# ATxmega128A1U device description
Architecture: AVR8_XMEGA; Family: AVR XMEGA
Registers are 8-bit, access not given, no defined reset value unless marked. A register's access mark holds for its fields unless they carry their own. Offsets are from the block's base; [hi:lo] are bit positions; {n}, {i} and the like mark numbered series; 'fields as' and 'values as' point back to an identical list.

## MCU — MCU Control
Instances: MCU 0x0090
{0x0+i} DEVID{i} (i=0..2) — Device ID byte {i}
0x03 REVID — Revision ID
0x04 JTAGUID — JTAG User ID
0x06 MCUCR — MCU Control
  [0] JTAGD — JTAG Disable
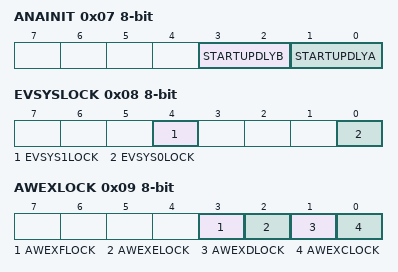
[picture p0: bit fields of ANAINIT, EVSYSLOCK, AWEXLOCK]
0x07 ANAINIT — Analog Startup Delay
  [3:2] STARTUPDLYB — Analog startup delay Port B
  [1:0] STARTUPDLYA — Analog startup delay Port A
0x08 EVSYSLOCK — Event System Lock
  [4] EVSYS1LOCK — Event Channel 4-7 Lock
  [0] EVSYS0LOCK — Event Channel 0-3 Lock
0x09 AWEXLOCK
  [3] AWEXFLOCK — AWeX on T/C F0 Lock
  [2] AWEXELOCK — AWeX on T/C E0 Lock
  [1] AWEXDLOCK — AWeX on T/C D0 Lock
  [0] AWEXCLOCK — AWeX on T/C C0 Lock

## PMIC — Programmable Multi-level Interrupt Controller
Instances: PMIC 0x00A0
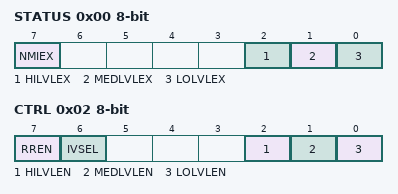
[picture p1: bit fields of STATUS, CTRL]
0x00 STATUS
  [7] NMIEX — Non-maskable Interrupt Executing
  [2] HILVLEX — High Level Interrupt Executing
  [1] MEDLVLEX — Medium Level Interrupt Executing
  [0] LOLVLEX — Low Level Interrupt Executing
0x01 INTPRI — Interrupt Priority
0x02 CTRL — Control Register
  [7] RREN — Round-Robin Priority Enable
  [6] IVSEL — Interrupt Vector Select
  [2] HILVLEN — High Level Enable
  [1] MEDLVLEN — Medium Level Enable
  [0] LOLVLEN — Low Level Enable

## PORTCFG — I/O port Configuration
Instances: PORTCFG 0x00B0
0x00 MPCMASK — Multi-pin Configuration Mask
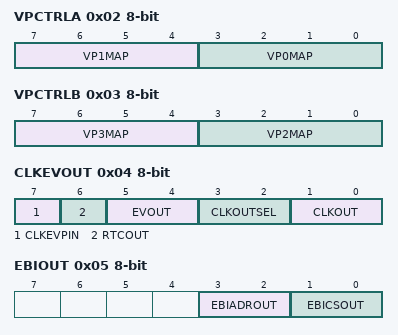
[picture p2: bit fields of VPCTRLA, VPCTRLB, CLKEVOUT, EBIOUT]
0x02 VPCTRLA — Virtual Port Control Register A
  [7:4] VP1MAP — Virtual Port 1 Mapping
    0=PORTA (Mapped To PORTA); 1=PORTB (Mapped To PORTB); 2=PORTC (Mapped To PORTC); 3=PORTD (Mapped To PORTD); 4=PORTE (Mapped To PORTE); 5=PORTF (Mapped To PORTF); 6=PORTG (Mapped To PORTG); 7=PORTH (Mapped To PORTH); 8=PORTJ (Mapped To PORTJ); 9=PORTK (Mapped To PORTK); 10=PORTL (Mapped To PORTL); 11=PORTM (Mapped To PORTM); 12=PORTN (Mapped To PORTN); 13=PORTP (Mapped To PORTP); 14=PORTQ (Mapped To PORTQ); 15=PORTR (Mapped To PORTR)
  [3:0] VP0MAP — Virtual Port 0 Mapping
    values as VP1MAP
0x03 VPCTRLB — Virtual Port Control Register B
  [7:4] VP3MAP — Virtual Port 3 Mapping
    values as VPCTRLA.VP1MAP
  [3:0] VP2MAP — Virtual Port 2 Mapping
    values as VPCTRLA.VP1MAP
0x04 CLKEVOUT — Clock and Event Out Register
  [7] CLKEVPIN — Peripheral Clock and Event Output pin Select
    0=PIN7 (Clock and Event Output on PIN 7); 1=PIN4 (Clock and Event Output on PIN 4)
  [6] RTCOUT — RTC Clock Output
  [5:4] EVOUT — Event Output Port
    0=OFF (Event Output Disabled); 1=PC7 (Event Channel 7 Output on Port C pin 7); 2=PD7 (Event Channel 7 Output on Port D pin 7); 3=PE7 (Event Channel 7 Output on Port E pin 7)
  [3:2] CLKOUTSEL — Peripheral Clock Output Select
    0=CLK1X (1x Peripheral Clock Output to pin); 1=CLK2X (2x Peripheral Clock Output to pin); 2=CLK4X (4x Peripheral Clock Output to pin)
  [1:0] CLKOUT — Peripheral Clock Output Port
    0=OFF (System Clock Output Disabled); 1=PC7 (System Clock Output on Port C pin 7); 2=PD7 (System Clock Output on Port D pin 7); 3=PE7 (System Clock Output on Port E pin 7)
0x05 EBIOUT — EBI Output register
  [3:2] EBIADROUT — EBI Address Output
    0=PF (EBI port 3 address output on PORTF pins 0 to 7); 1=PE (EBI port 3 address output on PORTE pins 0 to 7); 2=PFH (EBI port 3 address output on PORTF pins 4 to 7); 3=PEH (EBI port 3 address output on PORTE pins 4 to 7)
  [1:0] EBICSOUT — EBI Chip Select Output
    0=PH (EBI chip select output to PORTH pin 4 to 7); 1=PL (EBI chip select output to PORTL pin 4 to 7); 2=PF (EBI chip select output to PORTF pin 4 to 7); 3=PE (EBI chip select output to PORTE pin 4 to 7)
0x06 EVOUTSEL — Event Output Select
  [2:0] EVOUTSEL
    {v}=Event Channel {v} output to pin (v=0..7)

## AES — AES Module
Instances: AES 0x0C0
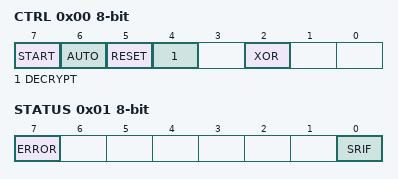
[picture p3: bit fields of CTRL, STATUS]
0x00 CTRL — AES Control Register
  [7] START — Start/Run
  [6] AUTO — Auto Start Trigger
  [5] RESET — AES Software Reset
  [4] DECRYPT — Decryption / Direction
  [2] XOR — State XOR Load Enable
0x01 STATUS — AES Status Register
  [7] ERROR — AES Error
  [0] SRIF — State Ready Interrupt Flag
0x02 STATE — AES State Register
0x03 KEY — AES Key Register
0x04 INTCTRL — AES Interrupt Control Register
  [1:0] INTLVL — Interrupt level
    0=OFF (Interrupt Disabled); 1=LO (Low Level); 2=MED (Medium Level); 3=HI (High Level)
